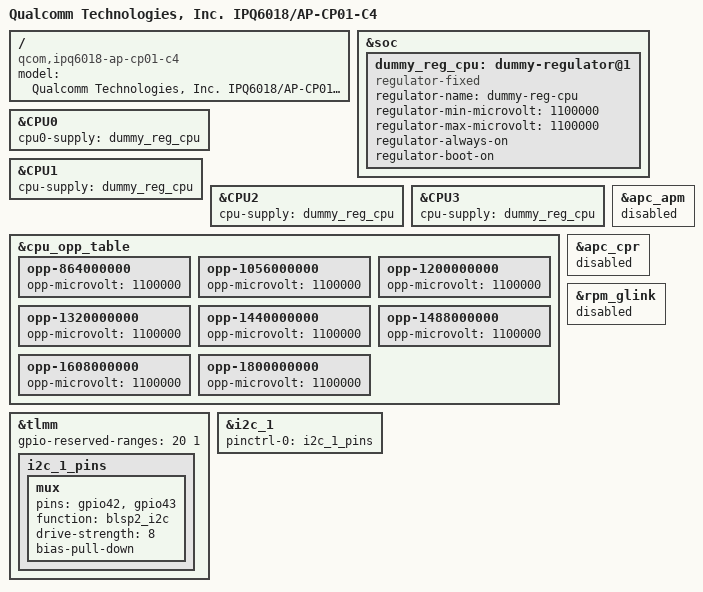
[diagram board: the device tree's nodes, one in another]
/dts-v1/;
/*
 * Copyright (c) 2020-2021, The Linux Foundation. All rights reserved.
 *
 * Permission to use, copy, modify, and/or distribute this software for any
 * purpose with or without fee is hereby granted, provided that the above
 * copyright notice and this permission notice appear in all copies.
 *
 * THE SOFTWARE IS PROVIDED "AS IS" AND THE AUTHOR DISCLAIMS ALL WARRANTIES
 * WITH REGARD TO THIS SOFTWARE INCLUDING ALL IMPLIED WARRANTIES OF
 * MERCHANTABILITY AND FITNESS. IN NO EVENT SHALL THE AUTHOR BE LIABLE FOR
 * ANY SPECIAL, DIRECT, INDIRECT, OR CONSEQUENTIAL DAMAGES OR ANY DAMAGES
 * WHATSOEVER RESULTING FROM LOSS OF USE, DATA OR PROFITS, WHETHER IN AN
 * ACTION OF CONTRACT, NEGLIGENCE OR OTHER TORTIOUS ACTION, ARISING OUT OF
 * OR IN CONNECTION WITH THE USE OR PERFORMANCE OF THIS SOFTWARE.
 */

#include "ipq6018-cp01.dtsi"
#include "ipq6018-cpr-regulator.dtsi"

/ {
	model = "Qualcomm Technologies, Inc. IPQ6018/AP-CP01-C4";
	compatible = "qcom,ipq6018-ap-cp01-c4", "qcom,ipq6018-ap-cp01", "qcom,ipq6018";
};

&soc {
	dummy_reg_cpu: dummy-regulator@1 {
		compatible = "regulator-fixed";
		regulator-name = "dummy-reg-cpu";
		regulator-min-microvolt = <1100000>;
		regulator-max-microvolt = <1100000>;
		regulator-always-on;
		regulator-boot-on;
	};
};

&CPU0 {
        cpu0-supply = <&dummy_reg_cpu>;
};

&CPU1 {
        cpu-supply = <&dummy_reg_cpu>;
};

&CPU2 {
        cpu-supply = <&dummy_reg_cpu>;
};

&CPU3 {
        cpu-supply = <&dummy_reg_cpu>;
};

&cpu_opp_table {
	/delete-node/ opp-0;
	opp-864000000 {
		opp-microvolt = <1100000>;
	};
	opp-1056000000 {
		opp-microvolt = <1100000>;
	};
	opp-1200000000 {
		opp-microvolt = <1100000>;
	};
	opp-1320000000 {
		opp-microvolt = <1100000>;
	};
	opp-1440000000 {
		opp-microvolt = <1100000>;
	};
	opp-1488000000 {
		opp-microvolt = <1100000>;
	};
	opp-1608000000 {
		opp-microvolt = <1100000>;
	};
	opp-1800000000 {
		opp-microvolt = <1100000>;
	};
};

&apc_apm {
	status = "disabled";
};

&apc_cpr {
	status = "disabled";
};

&tlmm {
	gpio-reserved-ranges = <20 1>;

	i2c_1_pins: i2c_1_pins {
		mux {
			pins = "gpio42", "gpio43";
			function = "blsp2_i2c";
			drive-strength = <8>;
			bias-pull-down;
		};
	};
};

&i2c_1 {
	pinctrl-0 = <&i2c_1_pins>;
	pinctrl-names = "default";
	status = "ok";
};

&rpm_glink {
	status = "disabled";
};
